AUTOSAR XML (schema 314)
package /ComponentType
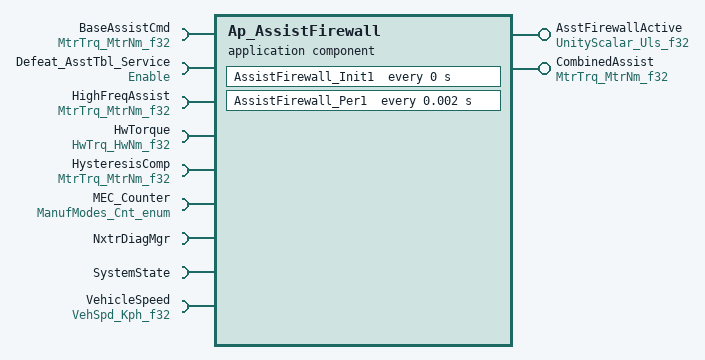
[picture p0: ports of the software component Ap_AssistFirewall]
  application software component type Ap_AssistFirewall
    provide port AsstFirewallActive: unqueued-sender-com-spec{data-element=Uls_f32, can-invalidate=false, init-value=D_ZERO_ULS_F32}, provided-interface=UnityScalar_Uls_f32
    provide port CombinedAssist: unqueued-sender-com-spec{data-element=MtrNm_f32, can-invalidate=false, init-value=D_ZERO_ULS_F32}, provided-interface=MtrTrq_MtrNm_f32
    9 x require port:
      BaseAssistCmd: unqueued-receiver-com-spec{data-element=MtrNm_f32, init-value=D_ZERO_ULS_F32}, required-interface=MtrTrq_MtrNm_f32
      Defeat_AsstTbl_Service: unqueued-receiver-com-spec{data-element=Cnt_lgc, init-value=D_FALSE_CNT_LGC}, required-interface=Enable
      HighFreqAssist: unqueued-receiver-com-spec{data-element=MtrNm_f32, init-value=D_ZERO_ULS_F32}, required-interface=MtrTrq_MtrNm_f32
      HwTorque: unqueued-receiver-com-spec{data-element=HwNm_f32, init-value=D_ZERO_ULS_F32}, required-interface=HwTrq_HwNm_f32
      HysteresisComp: unqueued-receiver-com-spec{data-element=MtrNm_f32, init-value=D_ZERO_ULS_F32}, required-interface=MtrTrq_MtrNm_f32
      MEC_Counter: unqueued-receiver-com-spec{data-element=Cnt_enum, init-value=D_MANUFMODEINIT_CNT_ENUM}, required-interface=ManufModes_Cnt_enum
      NxtrDiagMgr: required-com-specs=[GetNTCActive, GetNTCFailed, GetNTCStatus, SetNTCStatus], required-interface=NxtrDiagMgr
      SystemState: required-interface=SystemState
      VehicleSpeed: unqueued-receiver-com-spec{data-element=Kph_f32, init-value=D_ZERO_ULS_F32}, required-interface=VehSpd_Kph_f32
  internal behavior Ap_AssistFirewall_InternalBehavior: component=Ap_AssistFirewall
    timing event AssistFirewall_Init1_InitEvent: start-on-event=AssistFirewall_Init1, period=0
    timing event TMT_AssistFirewall_Per1: mode-dependency=dependent-on-mode=[SystemState.Mode.OFF, SystemState.Mode.WARMINIT], start-on-event=AssistFirewall_Per1, period=0.002
    port-api-options:
      enable-take-address=false, indirect-api=false, port=AsstFirewallActive
      enable-take-address=false, indirect-api=false, port=BaseAssistCmd
      enable-take-address=false, indirect-api=false, port=CombinedAssist
      enable-take-address=false, indirect-api=false, port=Defeat_AsstTbl_Service
      enable-take-address=false, indirect-api=false, port=HighFreqAssist
      enable-take-address=false, indirect-api=false, port=HwTorque
      enable-take-address=false, indirect-api=false, port=HysteresisComp
      enable-take-address=false, indirect-api=false, port=MEC_Counter
      enable-take-address=false, indirect-api=false, port=NxtrDiagMgr
      enable-take-address=false, indirect-api=false, port=SystemState
      enable-take-address=false, indirect-api=false, port=VehicleSpeed
    runnable AssistFirewall_Init1
    runnable AssistFirewall_Per1
      7 x data read access:
        READ_BaseAssistCmd_MtrNm_f32: data-element=BaseAssistCmd.MtrNm_f32
        READ_Defeat_AsstTbl_Service_Cnt_lgc: data-element=Defeat_AsstTbl_Service.Cnt_lgc
        READ_HighFreqAssist_MtrNm_f32: data-element=HighFreqAssist.MtrNm_f32
        READ_HwTorque_HwNm_f32: data-element=HwTorque.HwNm_f32
        READ_HysteresisComp_MtrNm_f32: data-element=HysteresisComp.MtrNm_f32
        READ_MEC_Counter_Cnt_enum: data-element=MEC_Counter.Cnt_enum
        READ_VehicleSpeed_Kph_f32: data-element=VehicleSpeed.Kph_f32
      data write access WRITE_AsstFirewallActive_Uls_f32: data-element=AsstFirewallActive.Uls_f32
      data write access WRITE_CombinedAssist_MtrNm_f32: data-element=CombinedAssist.MtrNm_f32
      sync call SC_NxtrDiagMgr_SetNTCStatus: operation=NxtrDiagMgr.SetNTCStatus, timeout=0
  swc implementation Ap_AssistFirewall_Implementation: behavior=Ap_AssistFirewall_InternalBehavior
    code-descriptors:
      code Code: type=SRC
